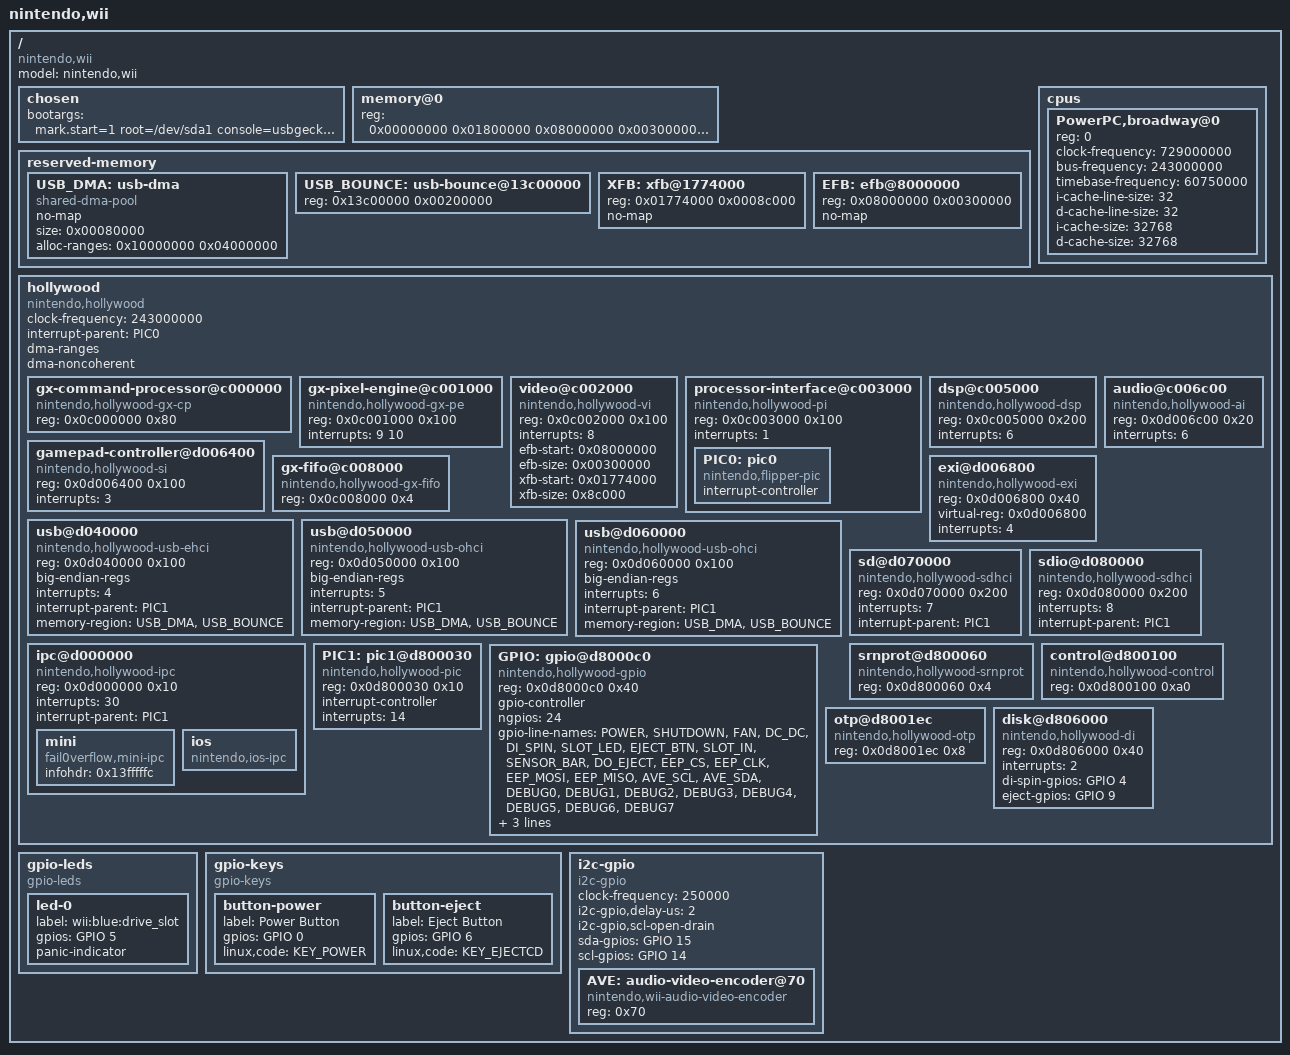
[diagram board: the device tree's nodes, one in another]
// SPDX-License-Identifier: GPL-2.0-or-later
/*
 * arch/powerpc/boot/dts/wii.dts
 *
 * Nintendo Wii platform device tree source
 * Copyright (C) 2008-2009 The GameCube Linux Team
 * Copyright (C) 2008,2009 Albert Herranz
 */

/dts-v1/;
#include <dt-bindings/gpio/gpio.h>
#include <dt-bindings/input/input.h>

/memreserve/ 0x10000000 0x0004000;	/* DSP RAM */
/memreserve/ 0x01800000 0xe800000;	/* memory hole */

/ {
	model = "nintendo,wii";
	compatible = "nintendo,wii";
	#address-cells = <1>;
	#size-cells = <1>;

	chosen {
		bootargs = "mark.start=1 root=/dev/sda1 console=usbgeckocon1 console=tty0      oops=panic force_keyboard_port=4 video=gcnfb:tv=auto rootwait dhash_entries=2048 ihash_entries=1024 panic=0             loglevel=8 consoleblank=0                          mark.end=1";
	};

	memory@0 {
		device_type = "memory";
		reg = <0x00000000 0x01800000	/* MEM1 24MB 1T-SRAM */
		       0x08000000 0x00300000	/* GX EFB 3MB EDRAM */
		       0x10000000 0x04000000>;	/* MEM2 64MB GDDR3 */
	};

	reserved-memory {
		#address-cells = <1>;
		#size-cells = <1>;
		ranges;

		USB_DMA: usb-dma {
			compatible = "shared-dma-pool";
			no-map;
			size = <0x00080000>; /* 512 KiB */
			alloc-ranges = <0x10000000 0x04000000>; /* MEM2 */
		};

		/*
		 * Cached MEM2 arena for bouncing MEM1-resident IN buffers.
		 * NOT no-map: it must stay in the kernel linear map so it is
		 * cacheable and phys_to_virt() is valid. Fixed address so the
		 * dynamic usb-dma allocation routes around it.
		 */
		USB_BOUNCE: usb-bounce@13c00000 {
			reg = <0x13c00000 0x00200000>; /* 2 MiB, MEM2 */
		};

		XFB: xfb@1774000 {
			reg = <0x01774000 0x0008c000>;
			no-map;
		};

		EFB: efb@8000000 {
			reg = <0x08000000 0x00300000>;
			no-map;
		};
	};

	cpus {
		#address-cells = <1>;
		#size-cells = <0>;

		PowerPC,broadway@0 {
			device_type = "cpu";
			reg = <0>;
			clock-frequency = <729000000>; /* 729MHz */
			bus-frequency = <243000000>; /* 243MHz core-to-bus 3x */
			timebase-frequency = <60750000>; /* 243MHz / 4 */
			i-cache-line-size = <32>;
			d-cache-line-size = <32>;
			i-cache-size = <32768>;
			d-cache-size = <32768>;
		};
	};

	/* devices contained in the hollywood chipset */
	hollywood {
		#address-cells = <1>;
		#size-cells = <1>;
		compatible = "nintendo,hollywood";
                ranges = <0x0c000000 0x0c000000 0x01000000
			  0x0d000000 0x0d000000 0x00800000
			  0x0d800000 0x0d800000 0x00800000>;
		clock-frequency = <243000000>; /* 243MHz */
		interrupt-parent = <&PIC0>;
		dma-ranges;
		dma-noncoherent;

		gx-command-processor@c000000 {
			compatible = "nintendo,hollywood-gx-cp",
					"nintendo,flipper-gx-cp";
			reg = <0x0c000000 0x80>;
		};

		gx-pixel-engine@c001000 {
			compatible = "nintendo,hollywood-gx-pe",
					"nintendo,flipper-gx-pe";
			reg = <0x0c001000 0x100>;
			interrupts = <9 10>;
		};

		video@c002000 {
			compatible = "nintendo,hollywood-vi",
					"nintendo,flipper-vi";
			reg = <0x0c002000 0x100>;
			interrupts = <8>;
			efb-start = <0x08000000>;
			efb-size = <0x00300000>;
			xfb-start = <0x01774000>; /* end-of-mem1 - xfb-size */
			xfb-size = <0x8c000>;     /* 640x448x2 bytes */
		};

		processor-interface@c003000 {
			compatible = "nintendo,hollywood-pi",
					"nintendo,flipper-pi";
			reg = <0x0c003000 0x100>;
			interrupts = <1>;

			PIC0: pic0 {
				#interrupt-cells = <1>;
				compatible = "nintendo,flipper-pic";
				interrupt-controller;
			};
		};

		dsp@c005000 {
			#address-cells = <1>;
			#size-cells = <1>;
			compatible = "nintendo,hollywood-dsp",
					"nintendo,flipper-dsp";
			reg = <0x0c005000 0x200>;
			interrupts = <6>;
		};

		gamepad-controller@d006400 {
			compatible = "nintendo,hollywood-si",
					"nintendo,flipper-si";
			reg = <0x0d006400 0x100>;
			interrupts = <3>;
		};

		audio@c006c00 {
			compatible = "nintendo,hollywood-ai",
					"nintendo,flipper-ai";
			reg = <0x0d006c00 0x20>;
			interrupts = <6>;
		};

		gx-fifo@c008000 {
			compatible = "nintendo,hollywood-gx-fifo",
					"nintendo,flipper-gx-fifo";
			reg = <0x0c008000 0x4>;
		};

		/* External Interface bus */
		exi@d006800 {
			compatible = "nintendo,hollywood-exi",
					"nintendo,flipper-exi";
			reg = <0x0d006800 0x40>;
			virtual-reg = <0x0d006800>;
			interrupts = <4>;
		};

		usb@d040000 {
			compatible = "nintendo,hollywood-usb-ehci";
			reg = <0x0d040000 0x100>;
			big-endian-regs;
			interrupts = <4>;
			interrupt-parent = <&PIC1>;
			memory-region = <&USB_DMA &USB_BOUNCE>;
		};

		usb@d050000 {
			compatible = "nintendo,hollywood-usb-ohci";
			reg = <0x0d050000 0x100>;
			big-endian-regs;
			interrupts = <5>;
			interrupt-parent = <&PIC1>;
			memory-region = <&USB_DMA &USB_BOUNCE>;
		};

		usb@d060000 {
			compatible = "nintendo,hollywood-usb-ohci";
			reg = <0x0d060000 0x100>;
			big-endian-regs;
			interrupts = <6>;
			interrupt-parent = <&PIC1>;
			memory-region = <&USB_DMA &USB_BOUNCE>;
		};

		sd@d070000 {
			compatible = "nintendo,hollywood-sdhci",
					"sdhci";
			reg = <0x0d070000 0x200>;
			interrupts = <7>;
			interrupt-parent = <&PIC1>;
		};

		sdio@d080000 {
			compatible = "nintendo,hollywood-sdhci",
					"sdhci";
			reg = <0x0d080000 0x200>;
			interrupts = <8>;
			interrupt-parent = <&PIC1>;
		};

		ipc@d000000 {
			compatible = "nintendo,hollywood-ipc";
			reg = <0x0d000000 0x10>;
			interrupts = <30>;
			interrupt-parent = <&PIC1>;

			mini {
				compatible = "fail0verflow,mini-ipc";
				infohdr = <0x13fffffc>; /* IPC infohdr */
			};

			ios {
				compatible = "nintendo,ios-ipc";
				/* TODO: how should this be defined? <0x133e0000 0x20000>; */ /* MEM2 reserved region */
			};
		};

		PIC1: pic1@d800030 {
			#interrupt-cells = <1>;
			compatible = "nintendo,hollywood-pic";
			reg = <0x0d800030 0x10>;
			interrupt-controller;
			interrupts = <14>;
		};

		srnprot@d800060 {
			compatible = "nintendo,hollywood-srnprot";
			reg = <0x0d800060 0x4>;
		};

		GPIO: gpio@d8000c0 {
			#gpio-cells = <2>;
			compatible = "nintendo,hollywood-gpio";
			reg = <0x0d8000c0 0x40>;
			gpio-controller;
			ngpios = <24>;

			gpio-line-names =
				"POWER", "SHUTDOWN", "FAN", "DC_DC",
				"DI_SPIN", "SLOT_LED", "EJECT_BTN", "SLOT_IN",
				"SENSOR_BAR", "DO_EJECT", "EEP_CS", "EEP_CLK",
				"EEP_MOSI", "EEP_MISO", "AVE_SCL", "AVE_SDA",
				"DEBUG0", "DEBUG1", "DEBUG2", "DEBUG3",
				"DEBUG4", "DEBUG5", "DEBUG6", "DEBUG7";

			interrupt-controller;
			#interrupt-cells = <2>;
			interrupts = <10>;
			interrupt-parent = <&PIC1>;
		};

		control@d800100 {
			compatible = "nintendo,hollywood-control";
			/*
			 * Both the address and length are wrong, according to
			 * Wiibrew this should be <0x0d800000 0x400>, but it
			 * requires refactoring the PIC1, GPIO and OTP nodes
			 * before changing that.
			 */
			reg = <0x0d800100 0xa0>;
		};

		otp@d8001ec {
			compatible = "nintendo,hollywood-otp";
			reg = <0x0d8001ec 0x8>;
		};

		disk@d806000 {
			compatible = "nintendo,hollywood-di";
			reg = <0x0d806000 0x40>;
			interrupts = <2>;
			di-spin-gpios = <&GPIO 4 GPIO_ACTIVE_HIGH>;
			eject-gpios = <&GPIO 9 GPIO_ACTIVE_HIGH>;
		};
	};

	gpio-leds {
		compatible = "gpio-leds";

		/* This is the blue LED in the disk drive slot */
		led-0 {
			label = "wii:blue:drive_slot";
			gpios = <&GPIO 5 GPIO_ACTIVE_HIGH>;
			panic-indicator;
		};
	};

	gpio-keys {
		compatible = "gpio-keys";

		button-power {
			label = "Power Button";
			gpios = <&GPIO 0 GPIO_ACTIVE_HIGH>;
			linux,code = <KEY_POWER>;
		};

		button-eject {
			label = "Eject Button";
			gpios = <&GPIO 6 GPIO_ACTIVE_HIGH>;
			linux,code = <KEY_EJECTCD>;
		};
	};

	i2c-gpio {
		#address-cells = <1>;
		#size-cells = <0>;
		compatible = "i2c-gpio";

		clock-frequency = <250000>;
		i2c-gpio,delay-us = <2>;

		/*
		 * Hollywood's GPIO controller doesn't allow changing the
		 * properties to open drain via the GPIO flags.  SDA has an
		 * external pull-up, so let gpiolib emulate open drain by
		 * switching it between output-low and input.  SCL has no
		 * external pull-up and must remain a push-pull output.
		 */
		i2c-gpio,scl-open-drain;

		sda-gpios = <&GPIO 15 GPIO_ACTIVE_HIGH>;
		scl-gpios = <&GPIO 14 GPIO_ACTIVE_HIGH>;

		AVE: audio-video-encoder@70 {
			compatible = "nintendo,wii-audio-video-encoder";
			reg = <0x70>;
		};
	};

};
